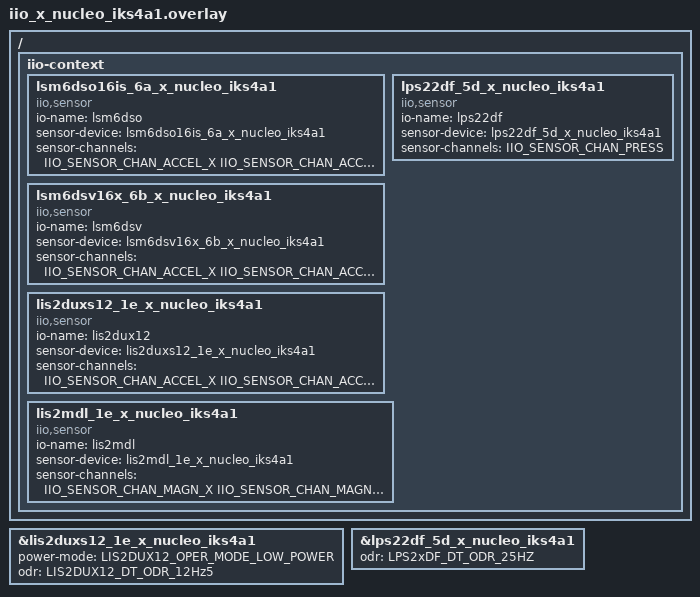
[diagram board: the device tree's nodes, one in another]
/*
 * Copyright (c) 2026 Analog Devices, Inc
 *
 * SPDX-License-Identifier: Apache-2.0
 */

#include <dt-bindings/iio/sensor-channels.h>
#include <zephyr/dt-bindings/sensor/lis2dux12.h>
#include <zephyr/dt-bindings/sensor/lps2xdf.h>

&lis2duxs12_1e_x_nucleo_iks4a1 {
	power-mode = <LIS2DUX12_OPER_MODE_LOW_POWER>;
	odr = <LIS2DUX12_DT_ODR_12Hz5>;
};

&lps22df_5d_x_nucleo_iks4a1 {
	odr = <LPS2xDF_DT_ODR_25HZ>;
};

/ {
	iio-context {
		lsm6dso16is_6a_x_nucleo_iks4a1 {
			compatible = "iio,sensor";
			io-name = "lsm6dso";
			sensor-device = <&lsm6dso16is_6a_x_nucleo_iks4a1>;
			sensor-channels = <
				IIO_SENSOR_CHAN_ACCEL_X
				IIO_SENSOR_CHAN_ACCEL_Y
				IIO_SENSOR_CHAN_ACCEL_Z
			>;
		};

		lsm6dsv16x_6b_x_nucleo_iks4a1 {
			compatible = "iio,sensor";
			io-name = "lsm6dsv";
			sensor-device = <&lsm6dsv16x_6b_x_nucleo_iks4a1>;
			sensor-channels = <
				IIO_SENSOR_CHAN_ACCEL_X
				IIO_SENSOR_CHAN_ACCEL_Y
				IIO_SENSOR_CHAN_ACCEL_Z
			>;
		};

		lis2duxs12_1e_x_nucleo_iks4a1 {
			compatible = "iio,sensor";
			io-name = "lis2dux12";
			sensor-device = <&lis2duxs12_1e_x_nucleo_iks4a1>;
			sensor-channels = <
				IIO_SENSOR_CHAN_ACCEL_X
				IIO_SENSOR_CHAN_ACCEL_Y
				IIO_SENSOR_CHAN_ACCEL_Z
				IIO_SENSOR_CHAN_DIE_TEMP
			>;
		};

		lps22df_5d_x_nucleo_iks4a1 {
			compatible = "iio,sensor";
			io-name = "lps22df";
			sensor-device = <&lps22df_5d_x_nucleo_iks4a1>;
			sensor-channels = <
				IIO_SENSOR_CHAN_PRESS
			>;
		};
		lis2mdl_1e_x_nucleo_iks4a1 {
			compatible = "iio,sensor";
			io-name = "lis2mdl";
			sensor-device = <&lis2mdl_1e_x_nucleo_iks4a1>;
			sensor-channels = <
				IIO_SENSOR_CHAN_MAGN_X
				IIO_SENSOR_CHAN_MAGN_Y
				IIO_SENSOR_CHAN_MAGN_Z
			>;
		};
	};
};
